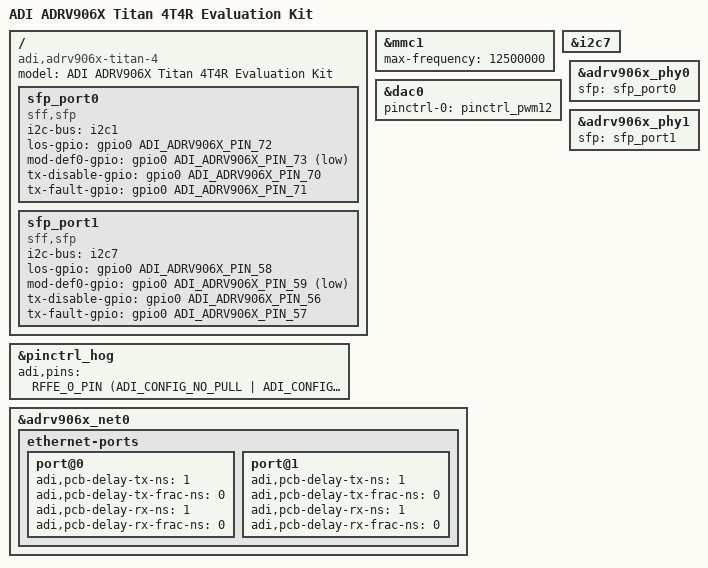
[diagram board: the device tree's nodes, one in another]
// SPDX-License-Identifier: GPL-2.0
/*
 * Copyright (c) 2024, Analog Devices Incorporated, All Rights Reserved
 */

/* For now, Titan-4 is identical to Denali-4 except for the changes below */
#include "adrv906x-denali-4.dts"

/ {
	model = "ADI ADRV906X Titan 4T4R Evaluation Kit";
	compatible = "adi,adrv906x-titan-4", "adi,adrv906x";

	sfp_port0: sfp_port0 {
		compatible = "sff,sfp";
		i2c-bus = <&i2c1>;
		los-gpio = <&gpio0 ADI_ADRV906X_PIN_72 GPIO_ACTIVE_HIGH>;
		mod-def0-gpio = <&gpio0 ADI_ADRV906X_PIN_73 GPIO_ACTIVE_LOW>;
		tx-disable-gpio = <&gpio0 ADI_ADRV906X_PIN_70 GPIO_ACTIVE_HIGH>;
		tx-fault-gpio = <&gpio0 ADI_ADRV906X_PIN_71 GPIO_ACTIVE_HIGH>;
	};

	sfp_port1: sfp_port1 {
		compatible = "sff,sfp";
		i2c-bus = <&i2c7>;
		los-gpio = <&gpio0 ADI_ADRV906X_PIN_58 GPIO_ACTIVE_HIGH>;
		mod-def0-gpio = <&gpio0 ADI_ADRV906X_PIN_59 GPIO_ACTIVE_LOW>;
		tx-disable-gpio = <&gpio0 ADI_ADRV906X_PIN_56 GPIO_ACTIVE_HIGH>;
		tx-fault-gpio = <&gpio0 ADI_ADRV906X_PIN_57 GPIO_ACTIVE_HIGH>;
	};
};

&mmc1 {
	/* BRINGUP TODO: Set this back to 50MHz */
	max-frequency = <12500000>;
};

&i2c7 {
	status = "okay";
};

&dac0 {
	status = "okay";
	pinctrl-names = "default";
	pinctrl-0 = <&pinctrl_pwm12>;
};

&pinctrl_hog {
	adi,pins = <
	/* RFFE signals */
	RFFE_0_PIN		(ADI_CONFIG_NO_PULL  | ADI_CONFIG_DRIVE_STRENGTH_4)
	RFFE_1_PIN		(ADI_CONFIG_NO_PULL  | ADI_CONFIG_DRIVE_STRENGTH_4)
	RFFE_2_PIN		(ADI_CONFIG_NO_PULL  | ADI_CONFIG_DRIVE_STRENGTH_4)
	RFFE_3_PIN		(ADI_CONFIG_NO_PULL  | ADI_CONFIG_DRIVE_STRENGTH_4)
	RFFE_4_PIN		(ADI_CONFIG_NO_PULL  | ADI_CONFIG_DRIVE_STRENGTH_4)
	RFFE_5_PIN		(ADI_CONFIG_NO_PULL  | ADI_CONFIG_DRIVE_STRENGTH_4)
	RFFE_6_PIN		(ADI_CONFIG_NO_PULL  | ADI_CONFIG_DRIVE_STRENGTH_4)
	RFFE_7_PIN		(ADI_CONFIG_NO_PULL  | ADI_CONFIG_DRIVE_STRENGTH_4)
	RFFE_8_PIN		(ADI_CONFIG_NO_PULL  | ADI_CONFIG_DRIVE_STRENGTH_4)
	RFFE_9_PIN		(ADI_CONFIG_NO_PULL  | ADI_CONFIG_DRIVE_STRENGTH_4)
	RFFE_10_PIN		(ADI_CONFIG_NO_PULL  | ADI_CONFIG_DRIVE_STRENGTH_4)
	RFFE_11_PIN		(ADI_CONFIG_NO_PULL  | ADI_CONFIG_DRIVE_STRENGTH_4)
	RFFE_12_PIN		(ADI_CONFIG_NO_PULL  | ADI_CONFIG_DRIVE_STRENGTH_4)
	RFFE_19_PIN		(ADI_CONFIG_NO_PULL  | ADI_CONFIG_DRIVE_STRENGTH_4)
	RFFE_20_PIN		(ADI_CONFIG_NO_PULL  | ADI_CONFIG_DRIVE_STRENGTH_4)
	RFFE_21_PIN		(ADI_CONFIG_NO_PULL  | ADI_CONFIG_DRIVE_STRENGTH_4)
	RFFE_22_PIN		(ADI_CONFIG_NO_PULL  | ADI_CONFIG_DRIVE_STRENGTH_4)
	RFFE_30_PIN		(ADI_CONFIG_NO_PULL  | ADI_CONFIG_DRIVE_STRENGTH_4)
	RFFE_31_PIN		(ADI_CONFIG_NO_PULL  | ADI_CONFIG_DRIVE_STRENGTH_4)
	RFFE_32_PIN		(ADI_CONFIG_NO_PULL  | ADI_CONFIG_DRIVE_STRENGTH_4)
	RFFE_33_PIN		(ADI_CONFIG_NO_PULL  | ADI_CONFIG_DRIVE_STRENGTH_4)
	RFFE_34_PIN		(ADI_CONFIG_NO_PULL  | ADI_CONFIG_DRIVE_STRENGTH_4)
	RFFE_37_PIN		(ADI_CONFIG_NO_PULL  | ADI_CONFIG_DRIVE_STRENGTH_4)
	RFFE_38_PIN		(ADI_CONFIG_NO_PULL  | ADI_CONFIG_DRIVE_STRENGTH_4)
	RFFE_39_PIN		(ADI_CONFIG_NO_PULL  | ADI_CONFIG_DRIVE_STRENGTH_4)
	RFFE_40_PIN		(ADI_CONFIG_NO_PULL  | ADI_CONFIG_DRIVE_STRENGTH_4)
	RFFE_44_PIN		(ADI_CONFIG_NO_PULL  | ADI_CONFIG_DRIVE_STRENGTH_4)
	RFFE_45_PIN		(ADI_CONFIG_NO_PULL  | ADI_CONFIG_DRIVE_STRENGTH_4)
	RFFE_46_PIN		(ADI_CONFIG_NO_PULL  | ADI_CONFIG_DRIVE_STRENGTH_4)

	/* Pin 51: Board pushbutton */
	A55_GPIO_NS_51_PIN	(ADI_CONFIG_ENABLE_SCHMITT_TRIGGER)

	/* Pins 56-59: SFP1 interface */
	A55_GPIO_NS_56_PIN	(ADI_CONFIG_NO_PULL  | ADI_CONFIG_DRIVE_STRENGTH_4)
	A55_GPIO_NS_57_PIN	(ADI_CONFIG_ENABLE_SCHMITT_TRIGGER)
	A55_GPIO_NS_58_PIN	(ADI_CONFIG_ENABLE_SCHMITT_TRIGGER)
	A55_GPIO_NS_59_PIN	(ADI_CONFIG_ENABLE_SCHMITT_TRIGGER)

	/* Pins 70-73: SFP0 interface */
	A55_GPIO_NS_70_PIN	(ADI_CONFIG_NO_PULL  | ADI_CONFIG_DRIVE_STRENGTH_4)
	A55_GPIO_NS_71_PIN	(ADI_CONFIG_ENABLE_SCHMITT_TRIGGER)
	A55_GPIO_NS_72_PIN	(ADI_CONFIG_ENABLE_SCHMITT_TRIGGER)
	A55_GPIO_NS_73_PIN	(ADI_CONFIG_ENABLE_SCHMITT_TRIGGER)

	/* Set all other pins as gpios */
/*	A55_GPIO_NS_0_PIN	(ADI_CONFIG_NO_PULL  | ADI_CONFIG_DRIVE_STRENGTH_4)
	A55_GPIO_NS_1_PIN	(ADI_CONFIG_NO_PULL  | ADI_CONFIG_DRIVE_STRENGTH_4)
	A55_GPIO_NS_2_PIN	(ADI_CONFIG_NO_PULL  | ADI_CONFIG_DRIVE_STRENGTH_4)
	A55_GPIO_NS_3_PIN	(ADI_CONFIG_NO_PULL  | ADI_CONFIG_DRIVE_STRENGTH_4)
	A55_GPIO_NS_4_PIN	(ADI_CONFIG_NO_PULL  | ADI_CONFIG_DRIVE_STRENGTH_4)
	A55_GPIO_NS_5_PIN	(ADI_CONFIG_NO_PULL  | ADI_CONFIG_DRIVE_STRENGTH_4)
	A55_GPIO_NS_6_PIN	(ADI_CONFIG_NO_PULL  | ADI_CONFIG_DRIVE_STRENGTH_4) SD */
/*	A55_GPIO_NS_7_PIN	(ADI_CONFIG_NO_PULL  | ADI_CONFIG_DRIVE_STRENGTH_4)
	A55_GPIO_NS_8_PIN	(ADI_CONFIG_NO_PULL  | ADI_CONFIG_DRIVE_STRENGTH_4)
	A55_GPIO_NS_9_PIN	(ADI_CONFIG_NO_PULL  | ADI_CONFIG_DRIVE_STRENGTH_4)
	A55_GPIO_NS_10_PIN	(ADI_CONFIG_NO_PULL  | ADI_CONFIG_DRIVE_STRENGTH_4)
	A55_GPIO_NS_11_PIN	(ADI_CONFIG_NO_PULL  | ADI_CONFIG_DRIVE_STRENGTH_4)
	A55_GPIO_NS_12_PIN	(ADI_CONFIG_NO_PULL  | ADI_CONFIG_DRIVE_STRENGTH_4)
	A55_GPIO_NS_13_PIN	(ADI_CONFIG_NO_PULL  | ADI_CONFIG_DRIVE_STRENGTH_4)
	A55_GPIO_NS_14_PIN	(ADI_CONFIG_NO_PULL  | ADI_CONFIG_DRIVE_STRENGTH_4)
	A55_GPIO_NS_15_PIN	(ADI_CONFIG_NO_PULL  | ADI_CONFIG_DRIVE_STRENGTH_4)
	A55_GPIO_NS_16_PIN	(ADI_CONFIG_NO_PULL  | ADI_CONFIG_DRIVE_STRENGTH_4)
	A55_GPIO_NS_17_PIN	(ADI_CONFIG_NO_PULL  | ADI_CONFIG_DRIVE_STRENGTH_4)
	A55_GPIO_NS_18_PIN	(ADI_CONFIG_NO_PULL  | ADI_CONFIG_DRIVE_STRENGTH_4)
	A55_GPIO_NS_19_PIN	(ADI_CONFIG_NO_PULL  | ADI_CONFIG_DRIVE_STRENGTH_4) RFFE signals */
/*	A55_GPIO_NS_20_PIN	(ADI_CONFIG_NO_PULL  | ADI_CONFIG_DRIVE_STRENGTH_4)
	A55_GPIO_NS_21_PIN	(ADI_CONFIG_NO_PULL  | ADI_CONFIG_DRIVE_STRENGTH_4) I2C 1 */
/*	A55_GPIO_NS_22_PIN	(ADI_CONFIG_NO_PULL  | ADI_CONFIG_DRIVE_STRENGTH_4)
	A55_GPIO_NS_23_PIN	(ADI_CONFIG_NO_PULL  | ADI_CONFIG_DRIVE_STRENGTH_4) Stream processor fault handling */
/*	A55_GPIO_NS_24_PIN	(ADI_CONFIG_NO_PULL  | ADI_CONFIG_DRIVE_STRENGTH_4)
	A55_GPIO_NS_25_PIN	(ADI_CONFIG_NO_PULL  | ADI_CONFIG_DRIVE_STRENGTH_4)
	A55_GPIO_NS_26_PIN	(ADI_CONFIG_NO_PULL  | ADI_CONFIG_DRIVE_STRENGTH_4)
	A55_GPIO_NS_27_PIN	(ADI_CONFIG_NO_PULL  | ADI_CONFIG_DRIVE_STRENGTH_4) UART 0 */
/*	A55_GPIO_NS_28_PIN	(ADI_CONFIG_NO_PULL  | ADI_CONFIG_DRIVE_STRENGTH_4) Not connected */
/*	A55_GPIO_NS_29_PIN	(ADI_CONFIG_NO_PULL  | ADI_CONFIG_DRIVE_STRENGTH_4) Not connected */
/*	A55_GPIO_NS_30_PIN	(ADI_CONFIG_NO_PULL  | ADI_CONFIG_DRIVE_STRENGTH_4)
	A55_GPIO_NS_31_PIN	(ADI_CONFIG_NO_PULL  | ADI_CONFIG_DRIVE_STRENGTH_4) UART 4, GNSS */
/*	A55_GPIO_NS_32_PIN	(ADI_CONFIG_NO_PULL  | ADI_CONFIG_DRIVE_STRENGTH_4) TF-A secure-partitioning: GPINT0 */
/*	A55_GPIO_NS_33_PIN	(ADI_CONFIG_NO_PULL  | ADI_CONFIG_DRIVE_STRENGTH_4)
	A55_GPIO_NS_34_PIN	(ADI_CONFIG_NO_PULL  | ADI_CONFIG_DRIVE_STRENGTH_4)
	A55_GPIO_NS_35_PIN	(ADI_CONFIG_NO_PULL  | ADI_CONFIG_DRIVE_STRENGTH_4)
	A55_GPIO_NS_36_PIN	(ADI_CONFIG_NO_PULL  | ADI_CONFIG_DRIVE_STRENGTH_4)
	A55_GPIO_NS_37_PIN	(ADI_CONFIG_NO_PULL  | ADI_CONFIG_DRIVE_STRENGTH_4) RFFE signals */
/*	A55_GPIO_NS_38_PIN	(ADI_CONFIG_NO_PULL  | ADI_CONFIG_DRIVE_STRENGTH_4)
	A55_GPIO_NS_39_PIN	(ADI_CONFIG_NO_PULL  | ADI_CONFIG_DRIVE_STRENGTH_4) I2C 7 */
/*	A55_GPIO_NS_40_PIN	(ADI_CONFIG_NO_PULL  | ADI_CONFIG_DRIVE_STRENGTH_4)
	A55_GPIO_NS_41_PIN	(ADI_CONFIG_NO_PULL  | ADI_CONFIG_DRIVE_STRENGTH_4) RFFE signals */
/*	A55_GPIO_NS_42_PIN	(ADI_CONFIG_NO_PULL  | ADI_CONFIG_DRIVE_STRENGTH_4) SPI_MASTER0_SELB_1_PIN */
/*	A55_GPIO_NS_43_PIN	(ADI_CONFIG_NO_PULL  | ADI_CONFIG_DRIVE_STRENGTH_4) RFFE signals */
/*	A55_GPIO_NS_44_PIN	(ADI_CONFIG_NO_PULL  | ADI_CONFIG_DRIVE_STRENGTH_4) Not connected */
/*	A55_GPIO_NS_45_PIN	(ADI_CONFIG_NO_PULL  | ADI_CONFIG_DRIVE_STRENGTH_4) ONE_PPS_CLK_OUTPUT_SE_PIN */
/*	A55_GPIO_NS_46_PIN	(ADI_CONFIG_NO_PULL  | ADI_CONFIG_DRIVE_STRENGTH_4) PWM_12_PIN */
/*	A55_GPIO_NS_47_PIN	(ADI_CONFIG_NO_PULL  | ADI_CONFIG_DRIVE_STRENGTH_4) RFFE signals */
	A55_GPIO_NS_48_PIN	(ADI_CONFIG_NO_PULL  | ADI_CONFIG_DRIVE_STRENGTH_4)
	A55_GPIO_NS_49_PIN	(ADI_CONFIG_NO_PULL  | ADI_CONFIG_DRIVE_STRENGTH_4)
	A55_GPIO_NS_50_PIN	(ADI_CONFIG_NO_PULL  | ADI_CONFIG_DRIVE_STRENGTH_4)
/*	A55_GPIO_NS_51_PIN	(ADI_CONFIG_NO_PULL  | ADI_CONFIG_DRIVE_STRENGTH_4) Board pushbutton */
/*	A55_GPIO_NS_52_PIN	(ADI_CONFIG_NO_PULL  | ADI_CONFIG_DRIVE_STRENGTH_4) Not connected */
/*	A55_GPIO_NS_53_PIN	(ADI_CONFIG_NO_PULL  | ADI_CONFIG_DRIVE_STRENGTH_4) Not connected */
/*	A55_GPIO_NS_54_PIN	(ADI_CONFIG_NO_PULL  | ADI_CONFIG_DRIVE_STRENGTH_4)
	A55_GPIO_NS_55_PIN	(ADI_CONFIG_NO_PULL  | ADI_CONFIG_DRIVE_STRENGTH_4) RFFE signals */
/*	A55_GPIO_NS_56_PIN	(ADI_CONFIG_NO_PULL  | ADI_CONFIG_DRIVE_STRENGTH_4)
	A55_GPIO_NS_57_PIN	(ADI_CONFIG_NO_PULL  | ADI_CONFIG_DRIVE_STRENGTH_4)
	A55_GPIO_NS_58_PIN	(ADI_CONFIG_NO_PULL  | ADI_CONFIG_DRIVE_STRENGTH_4)
	A55_GPIO_NS_59_PIN	(ADI_CONFIG_NO_PULL  | ADI_CONFIG_DRIVE_STRENGTH_4) QSFP interface */
/*	A55_GPIO_NS_60_PIN	(ADI_CONFIG_NO_PULL  | ADI_CONFIG_DRIVE_STRENGTH_4)
	A55_GPIO_NS_61_PIN	(ADI_CONFIG_NO_PULL  | ADI_CONFIG_DRIVE_STRENGTH_4)
	A55_GPIO_NS_62_PIN	(ADI_CONFIG_NO_PULL  | ADI_CONFIG_DRIVE_STRENGTH_4)
	A55_GPIO_NS_63_PIN	(ADI_CONFIG_NO_PULL  | ADI_CONFIG_DRIVE_STRENGTH_4)
	A55_GPIO_NS_64_PIN	(ADI_CONFIG_NO_PULL  | ADI_CONFIG_DRIVE_STRENGTH_4) JTAG A5 */
/*	A55_GPIO_NS_65_PIN	(ADI_CONFIG_NO_PULL  | ADI_CONFIG_DRIVE_STRENGTH_4)
	A55_GPIO_NS_66_PIN	(ADI_CONFIG_NO_PULL  | ADI_CONFIG_DRIVE_STRENGTH_4)
	A55_GPIO_NS_67_PIN	(ADI_CONFIG_NO_PULL  | ADI_CONFIG_DRIVE_STRENGTH_4)
	A55_GPIO_NS_68_PIN	(ADI_CONFIG_NO_PULL  | ADI_CONFIG_DRIVE_STRENGTH_4)
	A55_GPIO_NS_69_PIN	(ADI_CONFIG_NO_PULL  | ADI_CONFIG_DRIVE_STRENGTH_4) RFFE signals */
/*	A55_GPIO_NS_70_PIN	(ADI_CONFIG_NO_PULL  | ADI_CONFIG_DRIVE_STRENGTH_4)
	A55_GPIO_NS_71_PIN	(ADI_CONFIG_NO_PULL  | ADI_CONFIG_DRIVE_STRENGTH_4)
	A55_GPIO_NS_72_PIN	(ADI_CONFIG_NO_PULL  | ADI_CONFIG_DRIVE_STRENGTH_4)
	A55_GPIO_NS_73_PIN	(ADI_CONFIG_NO_PULL  | ADI_CONFIG_DRIVE_STRENGTH_4) QSFP interface */
/*	A55_GPIO_NS_74_PIN	(ADI_CONFIG_NO_PULL  | ADI_CONFIG_DRIVE_STRENGTH_4)
	A55_GPIO_NS_75_PIN	(ADI_CONFIG_NO_PULL  | ADI_CONFIG_DRIVE_STRENGTH_4)
	A55_GPIO_NS_76_PIN	(ADI_CONFIG_NO_PULL  | ADI_CONFIG_DRIVE_STRENGTH_4)
	A55_GPIO_NS_77_PIN	(ADI_CONFIG_NO_PULL  | ADI_CONFIG_DRIVE_STRENGTH_4) gpio-leds */
/*	A55_GPIO_NS_78_PIN	(ADI_CONFIG_NO_PULL  | ADI_CONFIG_DRIVE_STRENGTH_4)
	A55_GPIO_NS_79_PIN	(ADI_CONFIG_NO_PULL  | ADI_CONFIG_DRIVE_STRENGTH_4)
	A55_GPIO_NS_80_PIN	(ADI_CONFIG_NO_PULL  | ADI_CONFIG_DRIVE_STRENGTH_4)
	A55_GPIO_NS_81_PIN	(ADI_CONFIG_NO_PULL  | ADI_CONFIG_DRIVE_STRENGTH_4)
	A55_GPIO_NS_82_PIN	(ADI_CONFIG_NO_PULL  | ADI_CONFIG_DRIVE_STRENGTH_4)
	A55_GPIO_NS_83_PIN	(ADI_CONFIG_NO_PULL  | ADI_CONFIG_DRIVE_STRENGTH_4)
	A55_GPIO_NS_84_PIN	(ADI_CONFIG_NO_PULL  | ADI_CONFIG_DRIVE_STRENGTH_4) QSPI */
/*	A55_GPIO_NS_85_PIN	(ADI_CONFIG_NO_PULL  | ADI_CONFIG_DRIVE_STRENGTH_4)
	A55_GPIO_NS_86_PIN	(ADI_CONFIG_NO_PULL  | ADI_CONFIG_DRIVE_STRENGTH_4)
	A55_GPIO_NS_87_PIN	(ADI_CONFIG_NO_PULL  | ADI_CONFIG_DRIVE_STRENGTH_4)
	A55_GPIO_NS_88_PIN	(ADI_CONFIG_NO_PULL  | ADI_CONFIG_DRIVE_STRENGTH_4)
	A55_GPIO_NS_89_PIN	(ADI_CONFIG_NO_PULL  | ADI_CONFIG_DRIVE_STRENGTH_4)
	A55_GPIO_NS_90_PIN	(ADI_CONFIG_NO_PULL  | ADI_CONFIG_DRIVE_STRENGTH_4)
	A55_GPIO_NS_91_PIN	(ADI_CONFIG_NO_PULL  | ADI_CONFIG_DRIVE_STRENGTH_4)
	A55_GPIO_NS_92_PIN	(ADI_CONFIG_NO_PULL  | ADI_CONFIG_DRIVE_STRENGTH_4)
	A55_GPIO_NS_93_PIN	(ADI_CONFIG_NO_PULL  | ADI_CONFIG_DRIVE_STRENGTH_4)
	A55_GPIO_NS_94_PIN	(ADI_CONFIG_NO_PULL  | ADI_CONFIG_DRIVE_STRENGTH_4)
	A55_GPIO_NS_95_PIN	(ADI_CONFIG_NO_PULL  | ADI_CONFIG_DRIVE_STRENGTH_4)
	A55_GPIO_NS_96_PIN	(ADI_CONFIG_NO_PULL  | ADI_CONFIG_DRIVE_STRENGTH_4)
	A55_GPIO_NS_97_PIN	(ADI_CONFIG_NO_PULL  | ADI_CONFIG_DRIVE_STRENGTH_4)
	A55_GPIO_NS_98_PIN	(ADI_CONFIG_NO_PULL  | ADI_CONFIG_DRIVE_STRENGTH_4)
	A55_GPIO_NS_99_PIN	(ADI_CONFIG_NO_PULL  | ADI_CONFIG_DRIVE_STRENGTH_4)
	A55_GPIO_NS_100_PIN	(ADI_CONFIG_NO_PULL  | ADI_CONFIG_DRIVE_STRENGTH_4) EMAC */
/*	A55_GPIO_NS_101_PIN	(ADI_CONFIG_NO_PULL  | ADI_CONFIG_DRIVE_STRENGTH_4) TF-A secure-partitioning: GPINT_INTERRUPT_INPUT_SECONDARY_TO_PRIMARY_PIN */
/*	A55_GPIO_NS_102_PIN	(ADI_CONFIG_NO_PULL  | ADI_CONFIG_DRIVE_STRENGTH_4) TF-A secure-partitioning: A55_GPIO_S_102_PIN (reboot/shutdown signal to ADM12366) */
	>;
};

&adrv906x_phy0 {
	sfp = <&sfp_port0>;
};

&adrv906x_phy1 {
	sfp = <&sfp_port1>;
};

&adrv906x_net0 {
	ethernet-ports {
		port@0 {
			adi,pcb-delay-tx-ns = <1>;
			adi,pcb-delay-tx-frac-ns = <0>;
			adi,pcb-delay-rx-ns = <1>;
			adi,pcb-delay-rx-frac-ns = <0>;
		};
		port@1 {
			adi,pcb-delay-tx-ns = <1>;
			adi,pcb-delay-tx-frac-ns = <0>;
			adi,pcb-delay-rx-ns = <1>;
			adi,pcb-delay-rx-frac-ns = <0>;
		};
	};
};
